# f28004x_ecap_regs register map
Vendor: Texas Instruments
Peripheral module from a debugger description file (folder C2000).
Address unit: 16 bits
Registers are 32-bit, read-write, no defined reset value unless marked. A register's access mark holds for its fields unless they carry their own. Offsets are as the file gives them; lines under a group give offsets from that group; [hi:lo] are bit positions; {n}, {i} and the like mark numbered series; 'fields as' and 'values as' point back to an identical list; <NAME> marks a mode.

## ECAP_REGS — ECAP Registers
0x00 TSCTR — Time-Stamp Counter
  [31:0] TSCTR — Time Stamp Counter
0x02 CTRPHS — Counter Phase Offset Value Register
  [31:0] CTRPHS — Counter phase
{0x2+2i} CAP{i} (i=1..4) — Capture {i} Register
  [31:0] CAP{i} — Capture {i}
0x12 ECCTL0 — Capture Control Register 0
  [6:0] INPUTSEL — INPUT source select
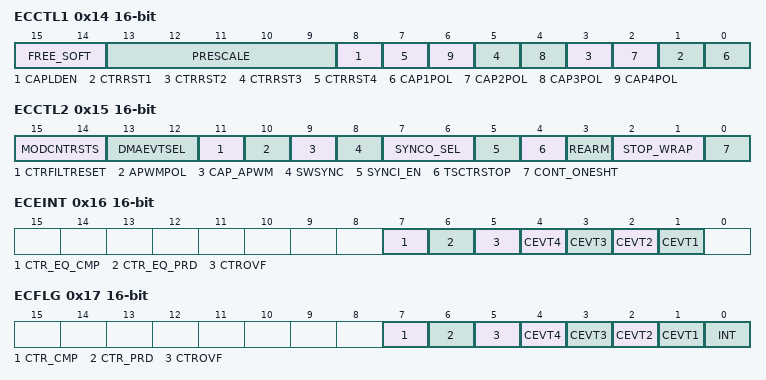
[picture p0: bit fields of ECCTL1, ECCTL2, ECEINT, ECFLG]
0x14 ECCTL1 16-bit — Capture Control Register 1
  [15:14] FREE_SOFT — Emulation mode
  [13:9] PRESCALE — Event Filter prescale select
  [8] CAPLDEN — Enable Loading CAP1-4 regs on a Cap Event
  [2n-1] CTRRST{n} (n=1..4) — Counter Reset on Capture Event {n}
  [2n-2] CAP{n}POL (n=1..4) — Capture Event {n} Polarity select
0x15 ECCTL2 16-bit access not given — Capture Control Register 2
  [15:14] MODCNTRSTS ro — modulo counter status
  [13:12] DMAEVTSEL rw — DMA event select
  [11] CTRFILTRESET — Reset event filter, counter. Module copunter and flags (access R=0/W=1)
  [10] APWMPOL rw — APWM output polarity select
  [9] CAP_APWM rw — CAP/APWM operating mode select
  [8] SWSYNC rw — SW forced counter sync
  [7:6] SYNCO_SEL rw — Sync-out mode
  [5] SYNCI_EN rw — Counter sync-in select
  [4] TSCTRSTOP rw — TSCNT counter stop
  [3] REARM rw — One-shot re-arm
  [2:1] STOP_WRAP rw — Stop value for one-shot, Wrap for continuous
  [0] CONT_ONESHT rw — Continuous or one-shot
0x16 ECEINT 16-bit — Capture Interrupt Enable Register
  [7] CTR_EQ_CMP — Compare Equal Interrupt Enable
  [6] CTR_EQ_PRD — Period Equal Interrupt Enable
  [5] CTROVF — Counter Overflow Interrupt Enable
  [n] CEVT{n} (n=1..4) — Capture Event {n} Interrupt Enable
0x17 ECFLG 16-bit ro — Capture Interrupt Flag Register
  [7] CTR_CMP — Compare Equal Interrupt Flag
  [6] CTR_PRD — Period Equal Interrupt Flag
  [5] CTROVF — Counter Overflow Interrupt Flag
  [n] CEVT{n} (n=1..4) — Capture Event {n} Interrupt Flag
  [0] INT — Global Flag
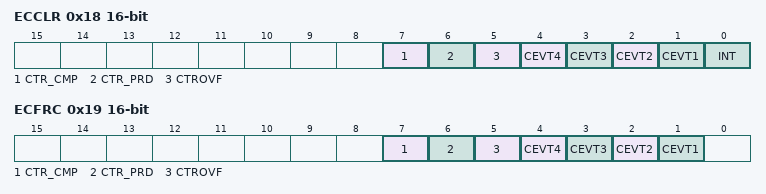
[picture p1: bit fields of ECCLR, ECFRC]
0x18 ECCLR 16-bit access not given — Capture Interrupt Clear Register
  [7] CTR_CMP — Compare Equal Status Clear (access R=0/W=1)
  [6] CTR_PRD — Period Equal Status Clear (access R=0/W=1)
  [5] CTROVF — Counter Overflow Status Clear (access R=0/W=1)
  [n] CEVT{n} (n=1..4) — Capture Event {n} Status Clear (access R=0/W=1)
  [0] INT — ECAP Global Interrupt Status Clear (access R=0/W=1)
0x19 ECFRC 16-bit — Capture Interrupt Force Register
  [7] CTR_CMP — Compare Equal Force Interrupt
  [6] CTR_PRD — Period Equal Force Interrupt
  [5] CTROVF — Counter Overflow Force Interrupt
  [n] CEVT{n} (n=1..4) — Capture Event {n} Force Interrupt
